# T113-S3 register map
Vendor: Allwinner; Series: T113-S3; File version: 0.1
CPU: other 0, little endian, MPU, no FPU, 0 interrupt priority bits
Registers are 32-bit, read-write, reset 0x0 unless marked. A register's access mark holds for its fields unless they carry their own. Offsets are from the block's base; [hi:lo] are bit positions; 'fields as' and 'values as' point back to an identical list.

## HSTimer
Base 0x03008000
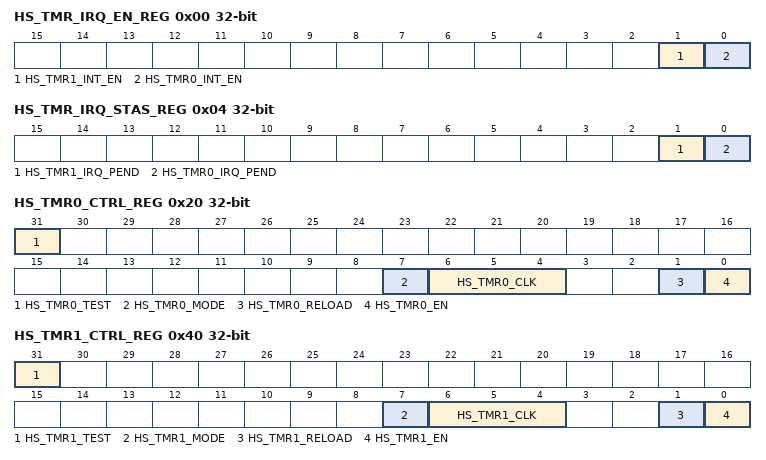
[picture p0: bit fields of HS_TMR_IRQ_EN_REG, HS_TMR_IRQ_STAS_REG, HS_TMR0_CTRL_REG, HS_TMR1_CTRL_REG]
0x00 HS_TMR_IRQ_EN_REG — HS Timer IRQ Enable Register
  [1] HS_TMR1_INT_EN — HSTimer1 Interrupt Enable 0: Disabled 1: Enabled
    0=Disabled; 1=Enabled
  [0] HS_TMR0_INT_EN — HSTimer0 Interrupt Enable 0: Disabled 1: Enabled
    0=Disabled; 1=Enabled
0x04 HS_TMR_IRQ_STAS_REG — HS Timer Status Register
  [1] HS_TMR1_IRQ_PEND write-1-clears — HSTimer1 IRQ Pending The IRQ pending bit for HSTimer1. Write 1 to clear the pending status. 0: No effect 1: Pending, indicates that the initial value of the HSTimer is reached.
    0=No_effect; 1=Pending, indicates that the initial value of the HSTimer is reached
  [0] HS_TMR0_IRQ_PEND write-1-clears — HSTimer0 IRQ Pending The IRQ pending bit for HSTimer0. Write 1 to clear the pending status. 0: No effect 1: Pending, indicates that the initial value of the HSTimer is reached.
    values as HS_TMR1_IRQ_PEND
0x20 HS_TMR0_CTRL_REG — HS Timer0 Control Register
  [31] HS_TMR0_TEST — Select the operating mode for HSTimer0 0: Normal mode 1: Test mode In the test mode, the HS_TMR0_INTV_LO_REG must be set to 0x1, and HS_TMR0_INTV_HI_REG acts as the initial value for HSTimer0.
    0=Normal_mode; 1=Test mode In the test mode, the HS_TMR0_INTV_LO_REG must be set to 0x1, and HS_TMR0_INTV_HI_REG acts as the initial value for HSTimer0
  [7] HS_TMR0_MODE — Select the timing mode for HSTimer0 0: Periodic mode. When the count value is decreased to 0, the timer will restart another round of counting automatically. 1: One-shot mode. When the count value is decreased to 0, the timer will stop counting.
    0=Periodic mode. When the count value is decreased to 0, the timer will restart another round of counting automatically.; 1=One-shot mode. When the count value is decreased to 0, the timer will stop counting.
  [6:4] HS_TMR0_CLK — Select the pre-scale for the HSTimer0 clock sources 000: /1 001: /2 010: /4 011: /8 100: /16 101: / 110: / 111: /
    0=_slash_1 (/1); 1=_slash_2 (/2); 2=_slash_4 (/4); 3=_slash_8 (/8); 4=_slash_16 (/16)
  [1] HS_TMR0_RELOAD write-1-sets — HSTimer0 Reload 0: No effect 1: Reload the interval value of the HSTimer0
    0=No_effect; 1=Reload the interval value of the HSTimer0
  [0] HS_TMR0_EN — HSTimer0 Enable 0: Stop/Pause 1: Start By setting the bit to 1, the timer will be started. It reloads the interval value register and then counts from the interval value to 0. By setting the bit to 0 before the timer counts to 0, the timer will be paused. The bit will be locked to 0 for at least 2 cycles. Within the 2 cycles, you cannot set the bit to 1 to restart the timer. The timer supports updating the interval value in the pause state. To start from the updated interval value, set both the reload bit and enable bit to 1. Additionally, in the one-shot mode, after the count value reaches 0, the system will automatically change the bit to 0 to stop the timer.
    0=Stop_slash_Pause (Stop/Pause); 1=Start By setting the bit to 1, the timer will be started. It reloads the interval value register and then counts from the interval value to 0. By setting the bit to 0 before the timer counts to 0, the timer will be paused. The bit will be locked to 0 for at least 2 cycles. Within the 2 cycles, you cannot set the bit to 1 to restart the timer. The timer supports updating the interval value in the pause state. To start from the updated interval value, set both the reload bit and enable bit to 1. Additionally, in the one-shot mode, after the count value reaches 0, the system will automatically change the bit to 0 to stop the timer.
0x24 HS_TMR0_INTV_LO_REG — HS Timer0 Interval Value Low Register
  [31:0] HS_TMR0_INTV_VALUE_LO — Bit[31:0] of the HSTimer0 interval value.
0x28 HS_TMR0_INTV_HI_REG — HS Timer0 Interval Value High Register
  [23:0] HS_TMR0_INTV_VALUE_HI — Bit[55:32] of the HSTimer0 interval value.
0x2C HS_TMR0_CURNT_LO_REG — HS Timer0 Current Value Low Register
  [31:0] HS_TMR0_CUR_VALUE_LO — Bit[31:0] of the HSTimer0 current value.
0x30 HS_TMR0_CURNT_HI_REG — HS Timer0 Current Value High Register
  [23:0] HS_TMR0_CUR_VALUE_HI — Bit[55:32] of the HSTimer0 current value.
0x40 HS_TMR1_CTRL_REG — HS Timer1 Control Register
  [31] HS_TMR1_TEST — Select the operating mode for HSTimer1. 0: Normal mode 1: Test mode In the test mode, the HS_TMR1_INTV_LO_REG must be set to 0x1, and HS_TMR1_INTV_HI_REG acts as the interval value for HSTimer1.
    0=Normal_mode; 1=Test mode In the test mode, the HS_TMR1_INTV_LO_REG must be set to 0x1, and HS_TMR1_INTV_HI_REG acts as the interval value for HSTimer1
  [7] HS_TMR1_MODE — Select the timing mode for HSTimer1. 0: Periodic mode. When the count value is decreased to 0, the timer will restart another round of counting automatically. 1: One-shot mode. When the count value is decreased to 0, the timer will stop counting.
    values as HS_TMR0_CTRL_REG.HS_TMR0_MODE
  [6:4] HS_TMR1_CLK — Select the pre-scale of the HSTimer1 clock sources. 000: /1 001: /2 010: /4 011: /8 100: /16 101: / 110: / 111: /
    values as HS_TMR0_CTRL_REG.HS_TMR0_CLK
  [1] HS_TMR1_RELOAD write-1-sets — HSTimer1 Reload 0: No effect 1: Reload the HSTimer1 interval value.
    0=No_effect; 1=Reload the HSTimer1 interval value
  [0] HS_TMR1_EN — HSTimer1 Enable 0: Stop/Pause 1: Start By setting the bit to 1, the timer will be started. It reloads the interval value register and then counts from the interval value to 0. By setting the bit to 0 before the timer counts to 0, the timer will be paused. The bit will be locked to 0 for at least 2 cycles. Within the 2 cycles, you cannot set the bit to 1 to restart the timer. The timer supports updating the interval value in the pause state. To start from the updated interval value, set both the reload bit and enable bit to 1. Additionally, in the one-shot mode, after the count value reaches 0, the system will automatically change the bit to 0 to stop the timer.
    values as HS_TMR0_CTRL_REG.HS_TMR0_EN
0x44 HS_TMR1_INTV_LO_REG — HS Timer1 Interval Value Low Register
  [31:0] HS_TMR1_INTV_VALUE_LO — Bit[31:0] of the HSTimer1 interval value
0x48 HS_TMR1_INTV_HI_REG — HS Timer1 Interval Value High Register
  [23:0] HS_TMR1_INTV_VALUE_HI — Bit[55:32] of the HSTimer1 interval value
0x4C HS_TMR1_CURNT_LO_REG — HS Timer1 Current Value Low Register
  [31:0] HS_TMR1_CUR_VALUE_LO — Bit[31:0] of the HSTimer1 current value
0x50 HS_TMR1_CURNT_HI_REG — HS Timer1 Current Value High Register
  [23:0] HS_TMR1_CUR_VALUE_HI — Bit[55:32] of the HSTimer1 current value
